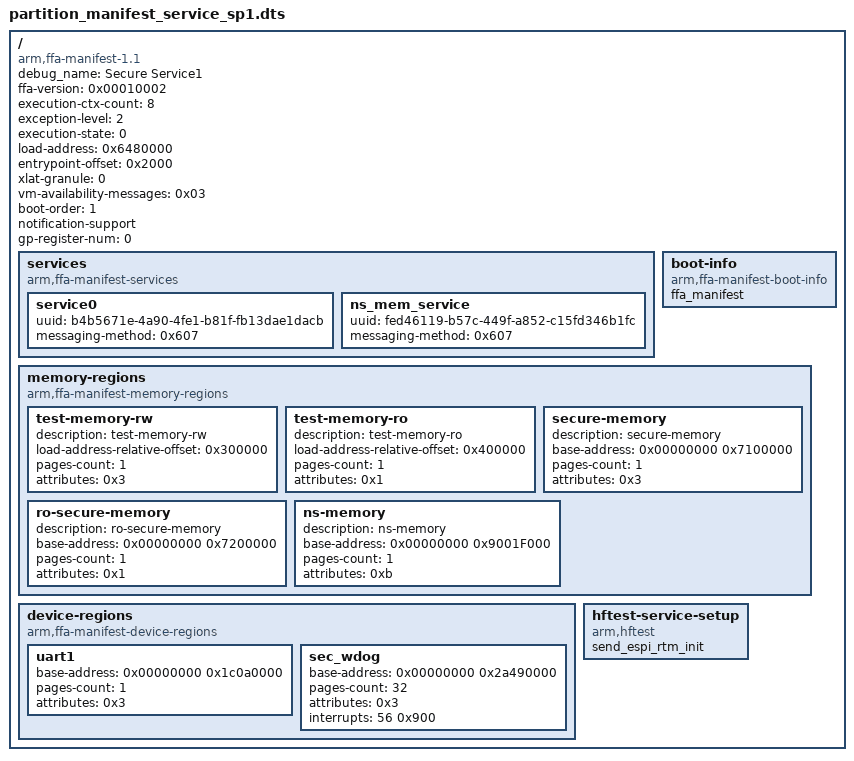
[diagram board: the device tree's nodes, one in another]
/*
 * Copyright 2022 The Hafnium Authors.
 *
 * Use of this source code is governed by a BSD-style
 * license that can be found in the LICENSE file or at
 * https://opensource.org/licenses/BSD-3-Clause.
 */

/dts-v1/;

/ {
	compatible = "arm,ffa-manifest-1.1";
	debug_name = "Secure Service1";

	/* Properties */
	ffa-version = <0x00010002>; /* 31:16 - Major, 15:0 - Minor */
	execution-ctx-count = <8>;
	exception-level = <2>; /* S-EL1 */
	execution-state = <0>; /* AARCH64 */
	load-address = <0x6480000>;
	entrypoint-offset = <0x2000>;
	xlat-granule = <0>; /* 4KiB */
	vm-availability-messages = <0x03>; /* Supports VM created and VM destroyed messages. */
	boot-order = <1>;
	notification-support; /* Receipt of notifications. */
	gp-register-num = <0>;

	services {
		compatible = "arm,ffa-manifest-services";

		service0 {
			uuid = "b4b5671e-4a90-4fe1-b81f-fb13dae1dacb";
			messaging-method = <0x607>; /* Supports direct (both APIs) and indirect requests. */
		};

		ns_mem_service {
			uuid = "fed46119-b57c-449f-a852-c15fd346b1fc"; /* Non-secure memory region uuid. */
			messaging-method = <0x607>;
		};
	};

	/* Boot Info */
	boot-info {
		compatible = "arm,ffa-manifest-boot-info";
		ffa_manifest;
	};

	memory-regions {

		compatible = "arm,ffa-manifest-memory-regions";

		test-memory-rw {
			description = "test-memory-rw";
			load-address-relative-offset = <0x300000>; /* effective address = 0x6780000 */
			pages-count = <1>;
			attributes = <0x3>; /* read-write */
		};

		test-memory-ro {
			description = "test-memory-ro";
			load-address-relative-offset = <0x400000>; /* effective address = 0x6780000 */
			pages-count = <1>;
			attributes = <0x1>; /* read-only */
		};

		secure-memory {
			description = "secure-memory";
			base-address = <0x00000000 0x7100000>;
			pages-count = <1>;
			attributes = <0x3>; /* read-write */
		};

		ro-secure-memory {
			description = "ro-secure-memory";
			base-address = <0x00000000 0x7200000>;
			pages-count = <1>;
			attributes = <0x1>; /* read-only */
		};

		ns-memory {
			description = "ns-memory";
			base-address = <0x00000000 0x9001F000>;
			pages-count = <1>;
			attributes = <0xb>; /* read-write and NS */
		};
	};

	device-regions {
		compatible = "arm,ffa-manifest-device-regions";

		uart1 {
			base-address = <0x00000000 0x1c0a0000>;
			pages-count = <1>;
			attributes = <0x3>; /* read-write */
		};

		sec_wdog {
			/* SP805 Trusted Watchdog Module */
			base-address = <0x00000000 0x2a490000>;
			pages-count = <32>; /* Two 64KB pages */
			attributes = <0x3>; /* read-write */
			interrupts = <56 0x900>;
		};
	};

	hftest-service-setup {
		compatible = "arm,hftest";
		send_espi_rtm_init;
	};
};
